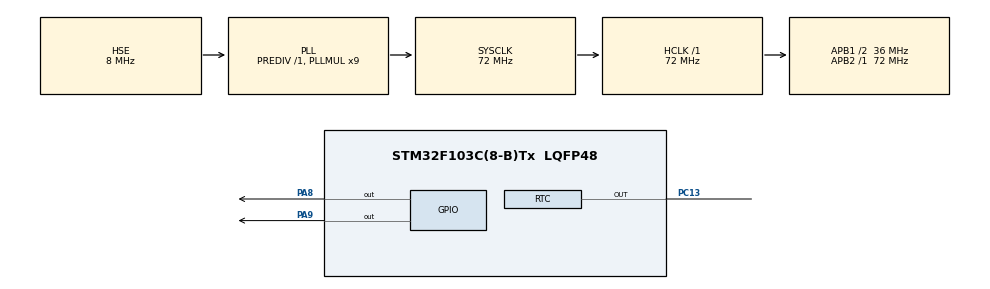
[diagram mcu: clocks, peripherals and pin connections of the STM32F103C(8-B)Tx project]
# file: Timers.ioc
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Mcu.Family=STM32F1
RCC.PLLSourceVirtual=RCC_PLLSOURCE_HSE
PC15-OSC32_OUT.Mode=LSE-External-Oscillator
Dma.ADC1.0.Instance=DMA1_Channel1
PD1-OSC_OUT.Mode=HSE-External-Oscillator
ADC1.ContinuousConvMode=ENABLE
PC13-TAMPER-RTC.Signal=RTC_OUT
VP_RTC_VS_RTC_Activate.Mode=RTC_Enabled
NVIC.TIM1_UP_IRQn=true\:0\:0\:false\:false\:true\:true\:true
PD0-OSC_IN.Signal=RCC_OSC_IN
RCC.APB1CLKDivider=RCC_HCLK_DIV2
PC14-OSC32_IN.Signal=RCC_OSC32_IN
RCC.SYSCLKSource=RCC_SYSCLKSOURCE_PLLCLK
ProjectManager.StackSize=0x400
PD1-OSC_OUT.Signal=RCC_OSC_OUT
RCC.ADCPresc=RCC_ADCPCLK2_DIV6
PA13.Signal=SYS_JTMS-SWDIO
Dma.ADC1.0.PeriphDataAlignment=DMA_PDATAALIGN_HALFWORD
TIM1.Prescaler=7199
ProjectManager.TargetToolchain=STM32CubeIDE
Dma.ADC1.0.Mode=DMA_CIRCULAR
RCC.HCLKFreq_Value=72000000
Dma.ADC1.0.Priority=DMA_PRIORITY_LOW
RCC.APB2TimFreq_Value=72000000
TIM3.Period=49999
PA9.Signal=GPIO_Output
ADC1.Channel-1\#ChannelRegularConversion=ADC_CHANNEL_VREFINT
Dma.ADC1.0.Direction=DMA_PERIPH_TO_MEMORY
RCC.USBFreq_Value=72000000
TIM4.Prescaler=7199
PC15-OSC32_OUT.Signal=RCC_OSC32_OUT
Dma.ADC1.0.MemDataAlignment=DMA_MDATAALIGN_HALFWORD
RCC.AHBFreq_Value=72000000
PD0-OSC_IN.Mode=HSE-External-Oscillator
PB3.Mode=Trace_Asynchronous_SW
board=custom
RCC.RTCClockSelection=RCC_RTCCLKSOURCE_LSE
RCC.PLLMUL=RCC_PLL_MUL9
PC13-TAMPER-RTC.Mode=RTC OUT
NVIC.TIM3_IRQn=true\:0\:0\:false\:false\:true\:true\:true
VP_ADC1_Vref_Input.Mode=IN-Vrefint
RCC.APB2Freq_Value=72000000
PC14-OSC32_IN.Mode=LSE-External-Oscillator
VP_TIM2_VS_ClockSourceINT.Mode=Internal
PA14.Mode=Trace_Asynchronous_SW
TIM3.Prescaler=7199
Dma.ADC1.0.PeriphInc=DMA_PINC_DISABLE
NVIC.TIM2_IRQn=true\:0\:0\:false\:false\:true\:true\:true
PA8.Signal=GPIO_Output
TIM2.Period=49999
TIM4.Period=49999
PA13.Mode=Trace_Asynchronous_SW
NVIC.RTC_Alarm_IRQn=true\:0\:0\:false\:false\:true\:true\:true
Mcu.Name=STM32F103C(8-B)Tx
VP_TIM1_VS_ClockSourceINT.Mode=Internal
PB3.Signal=SYS_JTDO-TRACESWO
ADC1.SamplingTime-1\#ChannelRegularConversion=ADC_SAMPLETIME_239CYCLES_5
RCC.SYSCLKFreq_VALUE=72000000
Mcu.Package=LQFP48
TIM2.Prescaler=7199
ADC1.master=1
ADC1.Rank-1\#ChannelRegularConversion=1
PA14.Signal=SYS_JTCK-SWCLK
Dma.ADC1.0.MemInc=DMA_MINC_ENABLE
ProjectManager.HeapSize=0x200
VP_TIM4_VS_ClockSourceINT.Mode=Internal
NVIC.PriorityGroup=NVIC_PRIORITYGROUP_4
ADC1.NbrOfConversionFlag=1
RCC.APB1TimFreq_Value=72000000
TIM1.Period=49999
NVIC.DMA1_Channel1_IRQn=true\:0\:0\:false\:false\:true\:false\:true
NVIC.TIM4_IRQn=true\:0\:0\:false\:false\:true\:true\:true
Dma.Request0=ADC1
RCC.APB1Freq_Value=36000000
RTC.Seconds_A-RTC\ OUT=5
VP_TIM3_VS_ClockSourceINT.Mode=Internal
PA8.PinState=GPIO_PIN_RESET

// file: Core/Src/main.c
/* USER CODE BEGIN Header */
/**
  ******************************************************************************
  * @file           : main.c
  * @brief          : Main program body
  ******************************************************************************
  * @attention
  *
  * <h2><center>&copy; Copyright (c) 2021 STMicroelectronics.
  * All rights reserved.</center></h2>
  *
  * This software component is licensed by ST under BSD 3-Clause license,
  * the "License"; You may not use this file except in compliance with the
  * License. You may obtain a copy of the License at:
  *                        opensource.org/licenses/BSD-3-Clause
  *
  ******************************************************************************
  */
/* USER CODE END Header */
#include "main.h"

/* USER CODE BEGIN Includes */
#define ADC_REFERENCE_VOLTAGE	1.2
#define ADC_MAX                 0xFFF
/* USER CODE END Includes */

ADC_HandleTypeDef hadc1;
DMA_HandleTypeDef hdma_adc1;

RTC_HandleTypeDef hrtc;

TIM_HandleTypeDef htim1;
TIM_HandleTypeDef htim2;
TIM_HandleTypeDef htim3;
TIM_HandleTypeDef htim4;

void SystemClock_Config(void);
static void MX_GPIO_Init(void);
static void MX_DMA_Init(void);
static void MX_TIM1_Init(void);
static void MX_TIM2_Init(void);
static void MX_TIM3_Init(void);
static void MX_TIM4_Init(void);
static void MX_RTC_Init(void);
static void MX_ADC1_Init(void);

/* USER CODE BEGIN 0 */
RTC_TimeTypeDef sTime = {0};
RTC_AlarmTypeDef sAlarm = {0};

int flag_sleeping_mode = 0;

void SetAlarm(){
	  /** set the Time */

//	  sTime.Hours = 0x00;
//	  sTime.Minutes = 0x00;
//	  sTime.Seconds = 0x00;

	  sTime.Hours = 0;
	  sTime.Minutes = 0;
	  sTime.Seconds = 0;

	  if (HAL_RTC_SetTime(&hrtc, &sTime, RTC_FORMAT_BIN) != HAL_OK)
	  {
	    Error_Handler();
	  }
	  /** Enable the Alarm A */
//	  sAlarm.AlarmTime.Hours = 0x00;
//	  sAlarm.AlarmTime.Minutes = 0x00;
//	  sAlarm.AlarmTime.Seconds = 0xA;

	  sAlarm.AlarmTime.Hours = 0;
	  sAlarm.AlarmTime.Minutes = 0;
	  sAlarm.AlarmTime.Seconds = 3;
	  sAlarm.Alarm = RTC_ALARM_A;
	  if (HAL_RTC_SetAlarm_IT(&hrtc, &sAlarm, RTC_FORMAT_BIN) != HAL_OK)
	  {
	    Error_Handler();
	  }
}

void HAL_TIM_PeriodElapsedCallback(TIM_HandleTypeDef *htim)
{
	if(htim->Instance == TIM1) //check if the interrupt comes from TIM1
	{
		HAL_GPIO_TogglePin(GPIOA, GPIO_PIN_8);
		flag_sleeping_mode = 1;
		SetAlarm();

		HAL_TIM_Base_Stop_IT(&htim1);
	}
}

void HAL_RTC_AlarmAEventCallback(RTC_HandleTypeDef *hrtc)
{
	HAL_GPIO_TogglePin(GPIOA, GPIO_PIN_9);
	//SystemClock_Config();
	//HAL_TIM_Base_Init(&htim1);

	//__HAL_TIM_CLEAR_FLAG(&htim1, TIM_SR_UIF);

	HAL_TIM_Base_Start_IT(&htim1);
}

/* USER CODE END 0 */

int main(void)
{

  /* MCU Configuration--------------------------------------------------------*/

  /* Reset of all peripherals, Initializes the Flash interface and the Systick. */
  HAL_Init();

  /* Configure the system clock */
  SystemClock_Config();

  /* Initialize all configured peripherals */
  MX_GPIO_Init();
  MX_DMA_Init();
  MX_TIM1_Init();
  MX_TIM2_Init();
  MX_TIM3_Init();
  MX_TIM4_Init();
  MX_RTC_Init();
  MX_ADC1_Init();
  /* USER CODE BEGIN 2 */
  __HAL_TIM_CLEAR_FLAG(&htim1, TIM_SR_UIF);
  //HAL_TIM_Base_Start_IT(&htim1);

  float mcuVoltage = 0;
  uint16_t adcData = 0;

  HAL_ADCEx_Calibration_Start(&hadc1);
  HAL_ADC_Start_DMA(&hadc1, (uint32_t*)&adcData, 1);

  /* USER CODE END 2 */

  /* Infinite loop */
  /* USER CODE BEGIN WHILE */
  while (1)
  {
	  if(flag_sleeping_mode){
		  mcuVoltage = ADC_MAX * ADC_REFERENCE_VOLTAGE / adcData;
		  flag_sleeping_mode = 0;
		  //HAL_PWR_EnterSTOPMode(PWR_LOWPOWERREGULATOR_ON, PWR_STOPENTRY_WFI);
	  }

    /* USER CODE END WHILE */

  }
}

void SystemClock_Config(void)
{
  RCC_OscInitTypeDef RCC_OscInitStruct = {0};
  RCC_ClkInitTypeDef RCC_ClkInitStruct = {0};
  RCC_PeriphCLKInitTypeDef PeriphClkInit = {0};

  /** Initializes the RCC Oscillators according to the specified parameters
  * in the RCC_OscInitTypeDef structure.
  */
  RCC_OscInitStruct.OscillatorType = RCC_OSCILLATORTYPE_HSE|RCC_OSCILLATORTYPE_LSE;
  RCC_OscInitStruct.HSEState = RCC_HSE_ON;
  RCC_OscInitStruct.HSEPredivValue = RCC_HSE_PREDIV_DIV1;
  RCC_OscInitStruct.LSEState = RCC_LSE_ON;
  RCC_OscInitStruct.HSIState = RCC_HSI_ON;
  RCC_OscInitStruct.PLL.PLLState = RCC_PLL_ON;
  RCC_OscInitStruct.PLL.PLLSource = RCC_PLLSOURCE_HSE;
  RCC_OscInitStruct.PLL.PLLMUL = RCC_PLL_MUL9;
  if (HAL_RCC_OscConfig(&RCC_OscInitStruct) != HAL_OK)
  {
    Error_Handler();
  }
  /** Initializes the CPU, AHB and APB buses clocks
  */
  RCC_ClkInitStruct.ClockType = RCC_CLOCKTYPE_HCLK|RCC_CLOCKTYPE_SYSCLK
                              |RCC_CLOCKTYPE_PCLK1|RCC_CLOCKTYPE_PCLK2;
  RCC_ClkInitStruct.SYSCLKSource = RCC_SYSCLKSOURCE_PLLCLK;
  RCC_ClkInitStruct.AHBCLKDivider = RCC_SYSCLK_DIV1;
  RCC_ClkInitStruct.APB1CLKDivider = RCC_HCLK_DIV2;
  RCC_ClkInitStruct.APB2CLKDivider = RCC_HCLK_DIV1;

  if (HAL_RCC_ClockConfig(&RCC_ClkInitStruct, FLASH_LATENCY_2) != HAL_OK)
  {
    Error_Handler();
  }
  PeriphClkInit.PeriphClockSelection = RCC_PERIPHCLK_RTC|RCC_PERIPHCLK_ADC;
  PeriphClkInit.RTCClockSelection = RCC_RTCCLKSOURCE_LSE;
  PeriphClkInit.AdcClockSelection = RCC_ADCPCLK2_DIV6;
  if (HAL_RCCEx_PeriphCLKConfig(&PeriphClkInit) != HAL_OK)
  {
    Error_Handler();
  }
}

static void MX_ADC1_Init(void)
{

  ADC_ChannelConfTypeDef sConfig = {0};

  /** Common config
  */
  hadc1.Instance = ADC1;
  hadc1.Init.ScanConvMode = ADC_SCAN_DISABLE;
  hadc1.Init.ContinuousConvMode = ENABLE;
  hadc1.Init.DiscontinuousConvMode = DISABLE;
  hadc1.Init.ExternalTrigConv = ADC_SOFTWARE_START;
  hadc1.Init.DataAlign = ADC_DATAALIGN_RIGHT;
  hadc1.Init.NbrOfConversion = 1;
  if (HAL_ADC_Init(&hadc1) != HAL_OK)
  {
    Error_Handler();
  }
  /** Configure Regular Channel
  */
  sConfig.Channel = ADC_CHANNEL_VREFINT;
  sConfig.Rank = ADC_REGULAR_RANK_1;
  sConfig.SamplingTime = ADC_SAMPLETIME_239CYCLES_5;
  if (HAL_ADC_ConfigChannel(&hadc1, &sConfig) != HAL_OK)
  {
    Error_Handler();
  }

}

static void MX_RTC_Init(void)
{

  RTC_TimeTypeDef sTime = {0};
  RTC_DateTypeDef DateToUpdate = {0};
  RTC_AlarmTypeDef sAlarm = {0};

  /** Initialize RTC Only
  */
  hrtc.Instance = RTC;
  hrtc.Init.AsynchPrediv = RTC_AUTO_1_SECOND;
  hrtc.Init.OutPut = RTC_OUTPUTSOURCE_ALARM;
  if (HAL_RTC_Init(&hrtc) != HAL_OK)
  {
    Error_Handler();
  }

  /** Initialize RTC and set the Time and Date
  */
  sTime.Hours = 0x0;
  sTime.Minutes = 0x0;
  sTime.Seconds = 0x0;

  if (HAL_RTC_SetTime(&hrtc, &sTime, RTC_FORMAT_BCD) != HAL_OK)
  {
    Error_Handler();
  }
  DateToUpdate.WeekDay = RTC_WEEKDAY_MONDAY;
  DateToUpdate.Month = RTC_MONTH_JANUARY;
  DateToUpdate.Date = 0x1;
  DateToUpdate.Year = 0x0;

  if (HAL_RTC_SetDate(&hrtc, &DateToUpdate, RTC_FORMAT_BCD) != HAL_OK)
  {
    Error_Handler();
  }
  /** Enable the Alarm A
  */
  sAlarm.AlarmTime.Hours = 0x0;
  sAlarm.AlarmTime.Minutes = 0x0;
  sAlarm.AlarmTime.Seconds = 0x5;
  sAlarm.Alarm = RTC_ALARM_A;
  if (HAL_RTC_SetAlarm_IT(&hrtc, &sAlarm, RTC_FORMAT_BCD) != HAL_OK)
  {
    Error_Handler();
  }

}

static void MX_TIM1_Init(void)
{

  TIM_ClockConfigTypeDef sClockSourceConfig = {0};
  TIM_MasterConfigTypeDef sMasterConfig = {0};

  htim1.Instance = TIM1;
  htim1.Init.Prescaler = 7199;
  htim1.Init.CounterMode = TIM_COUNTERMODE_UP;
  htim1.Init.Period = 49999;
  htim1.Init.ClockDivision = TIM_CLOCKDIVISION_DIV1;
  htim1.Init.RepetitionCounter = 0;
  htim1.Init.AutoReloadPreload = TIM_AUTORELOAD_PRELOAD_DISABLE;
  if (HAL_TIM_Base_Init(&htim1) != HAL_OK)
  {
    Error_Handler();
  }
  sClockSourceConfig.ClockSource = TIM_CLOCKSOURCE_INTERNAL;
  if (HAL_TIM_ConfigClockSource(&htim1, &sClockSourceConfig) != HAL_OK)
  {
    Error_Handler();
  }
  sMasterConfig.MasterOutputTrigger = TIM_TRGO_RESET;
  sMasterConfig.MasterSlaveMode = TIM_MASTERSLAVEMODE_DISABLE;
  if (HAL_TIMEx_MasterConfigSynchronization(&htim1, &sMasterConfig) != HAL_OK)
  {
    Error_Handler();
  }

}

static void MX_TIM2_Init(void)
{

  TIM_ClockConfigTypeDef sClockSourceConfig = {0};
  TIM_MasterConfigTypeDef sMasterConfig = {0};

  htim2.Instance = TIM2;
  htim2.Init.Prescaler = 7199;
  htim2.Init.CounterMode = TIM_COUNTERMODE_UP;
  htim2.Init.Period = 49999;
  htim2.Init.ClockDivision = TIM_CLOCKDIVISION_DIV1;
  htim2.Init.AutoReloadPreload = TIM_AUTORELOAD_PRELOAD_DISABLE;
  if (HAL_TIM_Base_Init(&htim2) != HAL_OK)
  {
    Error_Handler();
  }
  sClockSourceConfig.ClockSource = TIM_CLOCKSOURCE_INTERNAL;
  if (HAL_TIM_ConfigClockSource(&htim2, &sClockSourceConfig) != HAL_OK)
  {
    Error_Handler();
  }
  sMasterConfig.MasterOutputTrigger = TIM_TRGO_RESET;
  sMasterConfig.MasterSlaveMode = TIM_MASTERSLAVEMODE_DISABLE;
  if (HAL_TIMEx_MasterConfigSynchronization(&htim2, &sMasterConfig) != HAL_OK)
  {
    Error_Handler();
  }

}

static void MX_TIM3_Init(void)
{

  TIM_ClockConfigTypeDef sClockSourceConfig = {0};
  TIM_MasterConfigTypeDef sMasterConfig = {0};

  htim3.Instance = TIM3;
  htim3.Init.Prescaler = 7199;
  htim3.Init.CounterMode = TIM_COUNTERMODE_UP;
  htim3.Init.Period = 49999;
  htim3.Init.ClockDivision = TIM_CLOCKDIVISION_DIV1;
  htim3.Init.AutoReloadPreload = TIM_AUTORELOAD_PRELOAD_DISABLE;
  if (HAL_TIM_Base_Init(&htim3) != HAL_OK)
  {
    Error_Handler();
  }
  sClockSourceConfig.ClockSource = TIM_CLOCKSOURCE_INTERNAL;
  if (HAL_TIM_ConfigClockSource(&htim3, &sClockSourceConfig) != HAL_OK)
  {
    Error_Handler();
  }
  sMasterConfig.MasterOutputTrigger = TIM_TRGO_RESET;
  sMasterConfig.MasterSlaveMode = TIM_MASTERSLAVEMODE_DISABLE;
  if (HAL_TIMEx_MasterConfigSynchronization(&htim3, &sMasterConfig) != HAL_OK)
  {
    Error_Handler();
  }

}

static void MX_TIM4_Init(void)
{

  TIM_ClockConfigTypeDef sClockSourceConfig = {0};
  TIM_MasterConfigTypeDef sMasterConfig = {0};

  htim4.Instance = TIM4;
  htim4.Init.Prescaler = 7199;
  htim4.Init.CounterMode = TIM_COUNTERMODE_UP;
  htim4.Init.Period = 49999;
  htim4.Init.ClockDivision = TIM_CLOCKDIVISION_DIV1;
  htim4.Init.AutoReloadPreload = TIM_AUTORELOAD_PRELOAD_DISABLE;
  if (HAL_TIM_Base_Init(&htim4) != HAL_OK)
  {
    Error_Handler();
  }
  sClockSourceConfig.ClockSource = TIM_CLOCKSOURCE_INTERNAL;
  if (HAL_TIM_ConfigClockSource(&htim4, &sClockSourceConfig) != HAL_OK)
  {
    Error_Handler();
  }
  sMasterConfig.MasterOutputTrigger = TIM_TRGO_RESET;
  sMasterConfig.MasterSlaveMode = TIM_MASTERSLAVEMODE_DISABLE;
  if (HAL_TIMEx_MasterConfigSynchronization(&htim4, &sMasterConfig) != HAL_OK)
  {
    Error_Handler();
  }

}

static void MX_DMA_Init(void)
{

  /* DMA controller clock enable */
  __HAL_RCC_DMA1_CLK_ENABLE();

  /* DMA interrupt init */
  /* DMA1_Channel1_IRQn interrupt configuration */
  HAL_NVIC_SetPriority(DMA1_Channel1_IRQn, 0, 0);
  HAL_NVIC_EnableIRQ(DMA1_Channel1_IRQn);

}

static void MX_GPIO_Init(void)
{
  GPIO_InitTypeDef GPIO_InitStruct = {0};

  /* GPIO Ports Clock Enable */
  __HAL_RCC_GPIOC_CLK_ENABLE();
  __HAL_RCC_GPIOD_CLK_ENABLE();
  __HAL_RCC_GPIOA_CLK_ENABLE();
  __HAL_RCC_GPIOB_CLK_ENABLE();

  /*Configure GPIO pin Output Level */
  HAL_GPIO_WritePin(GPIOA, GPIO_PIN_8|GPIO_PIN_9, GPIO_PIN_RESET);

  /*Configure GPIO pins : PA8 PA9 */
  GPIO_InitStruct.Pin = GPIO_PIN_8|GPIO_PIN_9;
  GPIO_InitStruct.Mode = GPIO_MODE_OUTPUT_PP;
  GPIO_InitStruct.Pull = GPIO_NOPULL;
  GPIO_InitStruct.Speed = GPIO_SPEED_FREQ_LOW;
  HAL_GPIO_Init(GPIOA, &GPIO_InitStruct);

}

void Error_Handler(void)
{
  __disable_irq();
  while (1)
  {
  }
}

/************************ (C) COPYRIGHT STMicroelectronics *****END OF FILE****/
